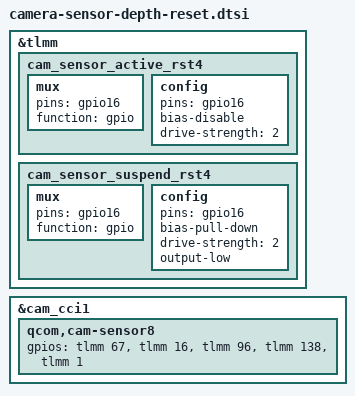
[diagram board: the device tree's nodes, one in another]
&tlmm {
	cam_sensor_active_rst4 {
		/* RESET 4 */
		mux {
			pins = "gpio16";
			function = "gpio";
		};

		config {
			pins = "gpio16";
			bias-disable; /* No PULL */
			drive-strength = <2>; /* 2 MA */
		};
	};

	cam_sensor_suspend_rst4 {
		/* RESET 4 */
		mux {
			pins = "gpio16";
			function = "gpio";
		};

		config {
			pins = "gpio16";
			bias-pull-down; /* PULL DOWN */
			drive-strength = <2>; /* 2 MA */
			output-low;
		};
	};
};

/* cci1: i2c2,i2c3 */
&cam_cci1 {
	/* rear depth senosr */
	qcom,cam-sensor8 {
		gpios = <&tlmm 67 0>, /* mclk3 gpio 67 */
			<&tlmm 16 0>, /* reset4 gpio 16 */
			<&tlmm 96 0>, /* pwdn4 gpio 96 */
			<&tlmm 138 0>, /* mcam_avdd gpio 138 */
			<&tlmm 1 0>; /* mcam_iovdd gpio 1 */
	};
};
